# SIM3L168_A register map
File version: 1
CPU: 
Registers are 32-bit, read-write, reset 0x0 unless marked. A register's access mark holds for its fields unless they carry their own. Offsets are from the block's base; [hi:lo] are bit positions; {n}, {i} and the like mark numbered series; 'fields as' and 'values as' point back to an identical list.

## ACCTR_0
Base 0x40042000
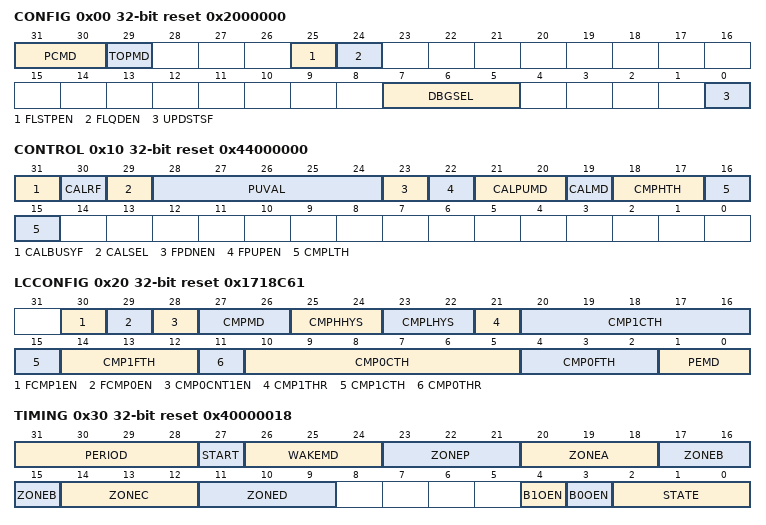
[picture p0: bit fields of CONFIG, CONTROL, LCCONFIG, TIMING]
0x00 CONFIG reset 0x2000000 — Configuration
  [31:30] PCMD — Pulse Counter Mode.
    0=DISABLED (Disable the pulse counter.); 1=SINGLE (Select single channel mode.); 2=DUAL (Select dual channel mode.); 3=QUADRATURE (Select quadrature mode.)
  [29] TOPMD — Topology Mode.
    0=SWITCH (Select the switch closure topology.); 1=LC (Select the LC resonant topology.)
  [25] FLSTPEN — Flutter Stop Enable.
    0=DISABLED (The pulse counter continues operating during a flutter event.); 1=ENABLED (The 24-bit counters stop counting during a flutter event.)
  [24] FLQDEN — Flutter Quadrature-to-Dual Switch Enable.
    0=DISABLED (The pulse counter remains in quadrature mode during a flutter event.); 1=ENABLED (The pulse counter switches from quadrature mode to dual mode during a flutter event.)
  [7:5] DBGSEL — Debug Signal Select.
    0=NONE (No debug signals output.); 1=LCC0_LCC1 ((LC Mode) DBG0 = CMP0OUT, DBG1 = CMP0OUT.); 2=LCC0_INT0 ((LC Mode) DBG0 = CMP0OUT, DBG1 = INTEG0.); 3=LCC1_INT1 ((LC Mode) DBG0 = CMP1OUT, DBG1 = INTEG1.); 4=INT0_INT1 ((Any Mode) DBG0 = INTEG0 DBG1 = INTEG1.); 5=CMP0_CMP1 ((Switch Mode) DBG0 = CMP0OUT, DBG1 = CMP0OUT.); 6=CMP0_INT0 ((Switch Mode) DBG0 = CMP0OUT, DBG1 = INTEG0.); 7=CMP1_INT1 ((Switch Mode) DBG0= CMP1OUT, DBG1 = INTEG1.)
  [0] UPDSTSF ro — Write Update Status Flag.
    0=NOT_SET (An internal pulse counter register update is not in progress.); 1=SET (An internal pulse counter register update is in progress.)
0x10 CONTROL reset 0x44000000
  [31] CALBUSYF — Calibration Busy Flag.
    0=NOT_SET (A calibration operation is not in progress.); 1=SET (A calibration operation is in progress. Hardware will clear this flag when the operation completes.)
  [30] CALRF ro — Calibration Result Flag.
    0=NOT_SET (The automatic calibration operation did not succeed.); 1=SET (The automatic calibration operation succeeded.)
  [29] CALSEL — Automatic Calibration Input Select.
    0=IN0 (Calibrate the IN0 input.); 1=IN1 (Calibrate the IN1 input.)
  [28:24] PUVAL — Pull-up Value.
  [23] FPDNEN — Force Ground Input Enable.
    0=DISABLED (Disable input grounding.); 1=ENABLED (Enable input grounding. The IN0 and IN1 inputs are grounded.)
  [22] FPUPEN — Force Continuous Pull-up Enable.
    0=DISABLED (Pull-ups are enabled automatically by hardware.); 1=ENABLED (Always enable the pull-ups.)
  [21:20] CALPUMD — Automatic Calibration Pull-up Mode.
    0=FULL (Use full pull-up mode.); 1=SMALL (Use small pull-up mode.); 2=MEDIUM (Use medium pull-up mode.); 3=LARGE (Use large pull-up mode.)
  [19] CALMD — Automatic Calibration Mode.
    0=UNTIL_PASS (Continue to calibrate until a passing condition occurs.); 1=UNTIL_FAIL (Continue to calibrate until a failing condition occurs.)
  [18:17] CMPHTH — Comparator High Threshold.
    0=48_PERCENT (Set the digital comparator high threshold to 48% of VIO.); 1=52_PERCENT (Set the digital comparator high threshold to 52% of VIO.); 2=56_PERCENT (Set the digital comparator high threshold to 56% of VIO.); 3=60_PERCENT (Set the digital comparator high threshold to 60% of VIO.)
  [16:15] CMPLTH — Comparator Low Threshold.
    0=32_PERCENT (Set the digital comparator low threshold to 32% of VIO.); 1=36_PERCENT (Set the digital comparator low threshold to 36% of VIO.); 2=40_PERCENT (Set the digital comparator low threshold to 40% of VIO.); 3=44_PERCENT (Set the digital comparator low threshold to 44% of VIO.)
0x20 LCCONFIG reset 0x1718C61 — LC Configuration
  [30] FCMP1EN — Force LC Comparator 1 On Enable.
    0=DISABLED (Hardware automatically turns LC comparator 1 on and off.); 1=ENABLED (Force LC comparator 1 always on.)
  [29] FCMP0EN — Force LC Comparator 0 On Enable.
    0=DISABLED (Hardware automatically turns LC comparator 0 on and off.); 1=ENABLED (Force LC comparator 0 always on.)
  [28] CMP0CNT1EN — LC Comparator 0 to Count 1 Enable.
    0=DISABLED (Use LC comparator 0 as an input to counter 0 and LC comparator 1 as an input to counter 1.); 1=ENABLED (Use LC comparator 0 as an input to both counter 0 and counter 1.)
  [27:26] CMPMD — LC Comparator Mode.
    0=5_US (Mode 0 (slowest response time, lowest power consumption).); 1=1_US (Mode 1.); 2=400_NS (Mode 2.); 3=200_NS (Mode 3 (fastest response time, highest power consumption).)
  [25:24] CMPHHYS — LC Comparator High-side Hysteresis.
    0=0_MV (Set both LC comparators to use 0 mV high-side hysteresis.); 1=5_MV (Set both LC comparators to use 5 mV high-side hysteresis.); 2=10_MV (Set both LC comparators to use 10 mV high-side hysteresis.); 3=20_MV (Set both LC comparators to use 20 mV high-side hysteresis.)
  [23:22] CMPLHYS — LC Comparator Low-side Hysteresis.
    0=0_MV (Set both LC comparators to use 0 mV low-side hysteresis.); 1=5_MV (Set both LC comparators to use 5 mV low-side hysteresis.); 2=10_MV (Set both LC comparators to use 10 mV low-side hysteresis.); 3=20_MV (Set both LC comparators to use 20 mV low-side hysteresis.)
  [21] CMP1THR — LC Comparator 1 Threshold Range.
    0=LOW (Set the comparator 1 threshold to the low range (0 V to VIO/8 in 48 steps).); 1=FULL (Set the comparator 1 threshold to a full range (0 V to VIO in 64 steps).)
  [20:15] CMP1CTH — LC Comparator 1 Coarse Threshold.
  [14:12] CMP1FTH — LC Comparator 1 Fine Threshold.
  [11] CMP0THR — LC Comparator 0 Threshold Range.
    0=LOW (Set the comparator 0 threshold to the low range (0 V to VIO/8 in 48 steps).); 1=FULL (Set the comparator 0 threshold to a full range (0 V to VIO in 64 steps).)
  [10:5] CMP0CTH — LC Comparator 0 Coarse Threshold.
  [4:2] CMP0FTH — LC Comparator 0 Fine Threshold.
  [1:0] PEMD — LC Pulse Extension Mode.
    0=LOW (Stretch the LC comparator output low pulses by approximately 20 ns.); 1=HIGH (Stretch the LC comparator output high pulses by approximately 20 ns.); 2=NONE (No pulse extension.)
0x30 TIMING reset 0x40000018
  [31:28] PERIOD — Pulse Counter Period.
    0=4_CYCLES (Set the period to 4 RTC cycles.); 1=8_CYCLES (Set the period to 8 RTC cycles.); 2=16_CYCLES (Set the period to 16 RTC cycles.); 3=32_CYCLES (Set the period to 32 RTC cycles.); 4=64_CYCLES (Set the period to 64 RTC cycles.); 5=128_CYCLES (Set the period to 128 RTC cycles.); 6=256_CYCLES (Set the period to 256 RTC cycles.); 7=512_CYCLES (Set the period to 512 RTC cycles.); 8=1024_CYCLES (Set the period to 1024 RTC cycles.); 9=2048_CYCLES (Set the period to 2048 RTC cycles.); 10=4096_CYCLES (Set the period to 4096 RTC cycles.); 14=SINGLE_SAMPLE (Set the module to single sample mode and disable the period counter after the next completion of the sequencer. In this mode, firmware must start each sample by setting FLCSEN to 1.); 15=CONSECUTIVE_SAMPLE (Set the module to consecutive sample mode and disable the period counter. After completing zone D, the timing engine will jump directly to zone A, skipping both the W and P zones.)
  [27] START — Sequencer Start.
    0=DISABLED (Do not start the sequencer.); 1=ENABLED (Start the sequencer.)
  [26:24] WAKEMD — LC Wake Mode.
    0=DISABLED (Disable wake up events.); 1=WZONEP (Wake or interrupt at the start of zone P.); 2=WZONEA (Wake or interrupt at the start of zone A.); 3=WZONEB (Wake or interrupt at the start of zone B.); 4=WZONEC (Wake or interrupt at the start of zone C.); 5=WZONED (Wake or interrupt at the start of zone D.); 6=WEND (Wake or interrupt at the end of the LC sequence.); 7=WKSTOP (Wake or interrupt at the end of the LC sequence and stop the sequencer when this event occurs.)
  [23:21] ZONEP — Zone P Count.
  [20:18] ZONEA — Zone A Count.
  [17:15] ZONEB — Zone B Count.
  [14:12] ZONEC — Zone C Count.
  [11:9] ZONED — Zone D Count.
  [4] B1OEN — Bias 1 Offset Enable.
    0=DISABLED (The bias 1 pulse is a full width (minimum 2 RTC cycles).); 1=ENABLED (The bias 1 pulse is delayed 1/2 an RTC cycle and de-asserts 1/2 an RTC cycle early (minimum 3 RTC cycles).)
  [3] B0OEN — Bias 0 Offset Enable.
    0=DISABLED (The bias 0 pulse is a full width (minimum 2 RTC cycles).); 1=ENABLED (The bias 0 pulse is delayed 1/2 an RTC cycle and de-asserts 1/2 an RTC cycle early (minimum 3 RTC cycles).)
  [2:0] STATE ro — Timing State.
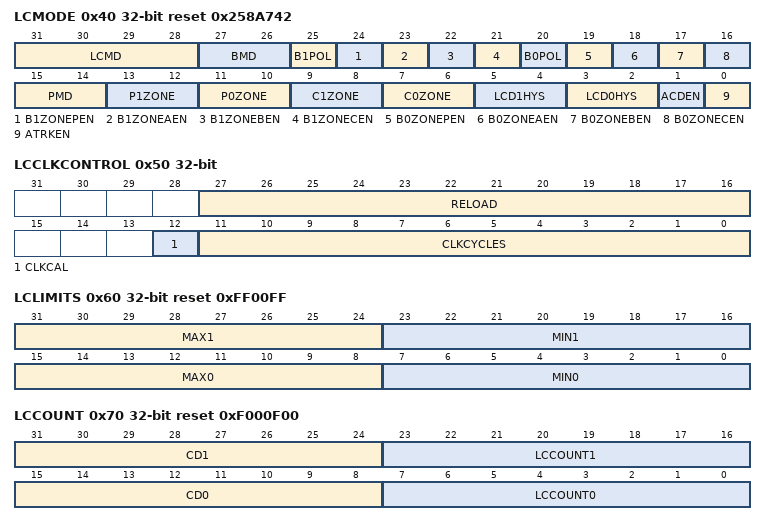
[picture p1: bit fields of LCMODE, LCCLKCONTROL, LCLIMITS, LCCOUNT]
0x40 LCMODE reset 0x258A742
  [31:28] LCMD — LC Mode.
    0=MODE0 (The LC pulse asserts throughout zone A or zone C with a single-ended comparator using the counter and discriminator.); 1=MODE1 (The LC pulse asserts throughout zone A or zone C with differential comparators using the counter and discriminator.); 2=MODE2 (The LC pulse asserts throughout zone A or zone C with a single-ended comparator sampling and holding at the end of the LC pulse.); 3=MODE3 (The LC pulse asserts throughout zone A or zone C with differential comparators sampling and holding at the end of the LC pulse.); 4=MODE4 (The LC pulse starts at the beginning of zone A or C and stops with the timer with a single-ended comparator using the counter and discriminator.); 5=MODE5 (The LC pulse starts at the beginning of zone A or C and stops with the timer with differential comparators using the counter and discriminator.); 6=MODE6 (The LC pulse starts at the beginning of zone A or C and stops with the timer with a single-ended comparator sampling and holding at the end of the LC pulse.); 7=MODE7 (The LC pulse starts at the beginning of zone A or C and stops with the timer with differential comparators sampling and holding at the end of the LC pulse.); 8=MODE8 (The LC pulse starts at beginning of zone A or C and stops with the rising edge of the external stop input (STOPx) with a single-ended comparator using the counter and discriminator.); 9=MODE9 (The LC pulse starts at beginning of zone A or C and stops with the falling edge of the external stop input (STOPx) with single-ended comparators using the counter and discriminator.); 10=MODE10 (The LC pulse starts at beginning of zone A or C and stops with the rising edge of the external stop input (STOPx) with a single-ended comparator sampling and holding at the end of the LC pulse.); 11=MODE11 (The LC pulse starts at beginning of zone A or C and stops with the falling edge of the external stop input (STOPx) with single-ended comparators sampling and holding at the end of the LC pulse.); 12=MODE12 (Do not generate a pulse with a single-ended comparator using the timer and discrimintor.); 13=MODE13 (Do not generate a pulse with differential comparators using the timer and discrimintor.); 14=MODE14 (Do not generate a pulse with a single-ended comparator sampling and holding at the end of the zone.); 15=MODE15 (Do not genreate a pulse with differential comparators sampling and holding at the end of the zone.)
  [27:26] BMD — Bias Mode.
    0=MODE0 (Disable the bias signals.); 1=MODE1 (Use the bias signals externally only (LCBIAS0 and LCBIAS1 outputs).); 2=MODE2 (Use the bias signals internally only.); 3=MODE3 (Use the bias signals externally (LCBIAS0 and LCBIAS1 outputs) and internally.)
  [25] B1POL — Bias 1 Polarity.
    0=PULSE_LOW (Set bias 1 to idle high, pulse low.); 1=PULSE_HIGH (Set bias 1 to idle low, pulse high.)
  [24] B1ZONEPEN — Bias 1 Zone P Enable.
    0=DISABLED (Disable bias 1 during zone P.); 1=ENABLED (Enable bias 1 during zone P.)
  [23] B1ZONEAEN — Bias 1 Zone A Enable.
    0=DISABLED (Disable bias 1 during zone A.); 1=ENABLED (Enable bias 1 during zone A.)
  [22] B1ZONEBEN — Bias 1 Zone B Enable.
    0=DISABLED (Disable bias 1 during zone B.); 1=ENABLED (Enable bias 1 during zone B.)
  [21] B1ZONECEN — Bias 1 Zone C Enable.
    0=DISABLED (Disable bias 1 during zone C.); 1=ENABLED (Enable bias 1 during zone C.)
  [20] B0POL — Bias 0 Polarity.
    0=PULSE_LOW (Set bias 0 to idle high, pulse low.); 1=PULSE_HIGH (Set bias 0 to idle low, pulse high.)
  [19] B0ZONEPEN — Bias 0 Zone P Enable.
    0=DISABLED (Disable bias 0 during zone P.); 1=ENABLED (Enable bias 0 during zone P.)
  [18] B0ZONEAEN — Bias 0 Zone A Enable.
    0=DISABLED (Disable bias 0 during zone A.); 1=ENABLED (Enable bias 0 during zone A.)
  [17] B0ZONEBEN — Bias 0 Zone B Enable.
    0=DISABLED (Disable bias 0 during zone B.); 1=ENABLED (Enable bias 0 during zone B.)
  [16] B0ZONECEN — Bias 0 Zone C Enable.
    0=DISABLED (Disable bias 0 during zone C.); 1=ENABLED (Enable bias 0 during zone C.)
  [15:14] PMD — LC Pulse Mode.
    0=DISABLED (Disable pulse mode.); 1=TOGGLE (Toggle at the start of zone A or zone C.); 2=PULSE_LOW (Set the pulse mode to idle high, pulse low.); 3=PULSE_HIGH (Set the pulse mode to idle low, pulse high.)
  [13:12] P1ZONE — Pulse 1 Active Zone Select.
    0=DISABLED (Disable the pulse 1 output (LCPUL1).); 1=C_ONLY (Select zone C only as the active zone for the pulse 1 output (LCPUL1).); 2=A_ONLY (Select zone A only as the active zone for the pulse 1 output (LCPUL1).); 3=A_AND_C (Select zones A and C as the active zones for the pulse 1 output (LCPUL1).)
  [11:10] P0ZONE — Pulse 0 Active Zone Select.
    0=DISABLED (Disable the pulse 0 output (LCPUL0).); 1=C_ONLY (Select zone C only as the active zone for the pulse 0 output (LCPUL0).); 2=A_ONLY (Select zone A only as the active zone for the pulse 0 output (LCPUL0).); 3=A_AND_C (Select zones A and C as the active zones for the pulse 0 output (LCPUL0).)
  [9:8] C1ZONE — Counter 1 Active Zone Select.
    0=ZONEA (Select zone A as the active zone for counter 1 (LCIN1 input).); 1=ZONEB (Select zone B as the active zone for counter 1 (LCIN1 input).); 2=ZONEC (Select zone C as the active zone for counter 1 (LCIN1 input).); 3=ZONED (Select zone D as the active zone for counter 1 (LCIN1 input).)
  [7:6] C0ZONE — Counter 0 Active Zone Select.
    0=ZONEA (Select zone A as the active zone for counter 0 (LCIN0 input).); 1=ZONEB (Select zone B as the active zone for counter 0 (LCIN0 input).); 2=ZONEC (Select zone C as the active zone for counter 0 (LCIN0 input).); 3=ZONED (Select zone D as the active zone for counter 0 (LCIN0 input).)
  [5:4] LCD1HYS — LC Discriminator 1 Digital Hysterisis.
    0=ZERO (A high-to-low transition occurs if LCCOUNT1 is less than CD1.); 1=MINUS1 (A high-to-low transition occurs if LCCOUNT1 is less than CD1 - 1.); 2=MINUS2 (A high-to-low transition occurs if LCCOUNT1 is less than CD1 - 2.); 3=MINUS3 (A high-to-low transition occurs if LCCOUNT1 is less than CD1 - 3.)
  [3:2] LCD0HYS — LC Discriminator 0 Digital Hysterisis.
    0=ZERO (A high-to-low transition occurs if LCCOUNT0 is less than CD0.); 1=MINUS1 (A high-to-low transition occurs if LCCOUNT0 is less than CD0 - 1.); 2=MINUS2 (A high-to-low transition occurs if LCCOUNT0 is less than CD0 - 2.); 3=MINUS3 (A high-to-low transition occurs if LCCOUNT0 is less than CD0 - 3.)
  [1] ACDEN — Automatic Center Discriminator Enable.
    0=DISABLED (Disable automatic center discriminator mode. Firmware must set the CD0 and CD1 fields.); 1=ENABLED (Enable automatic center discriminator mode. Hardware will keep the CD0 and CD1 fields centered between MAX and MIN.)
  [0] ATRKEN — Automatic Tracking Enable.
    0=DISABLED (Disable automatic tracking.); 1=ENABLED (Enable automatic tracking. A new MAX value of any size will increase both the MAX and MIN by 1, and a new MIN value of any size will decrease both the MAX and MIN by 1.)
0x50 LCCLKCONTROL — LC Clock Control
  [27:16] RELOAD — LC Oscillator Reload Value.
  [12] CLKCAL — LC Oscillator Calibration Start.
    0=NOT_IN_PROGRESS (A calibration operation is not in progress.); 1=START (Start an oscillator calibration or a calibration operation is in progress.)
  [11:0] CLKCYCLES ro — LC Oscillator Clock Cycles.
0x60 LCLIMITS reset 0xFF00FF — LC Counter Limits
  [31:24] MAX1 ro — LC Counter 1 Maximum Value.
  [23:16] MIN1 ro — LC Counter 1 Minimum Value.
  [15:8] MAX0 ro — LC Counter 0 Maximum Value.
  [7:0] MIN0 ro — LC Counter 0 Minimum Value.
0x70 LCCOUNT reset 0xF000F00 — LC Counters
  [31:24] CD1 — LC Counter 1 Discriminator.
  [23:16] LCCOUNT1 ro — LC Counter 1.
  [15:8] CD0 — LC Counter 0 Discriminator.
  [7:0] LCCOUNT0 ro — LC Counter 0.
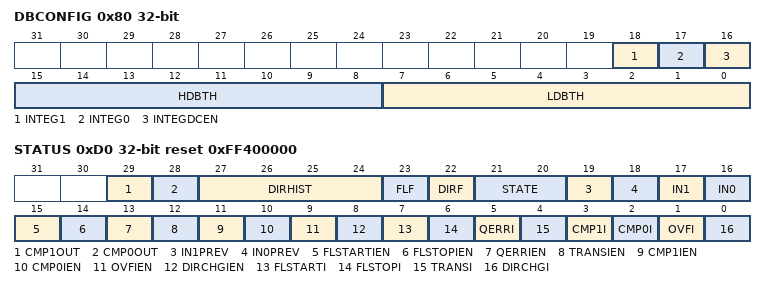
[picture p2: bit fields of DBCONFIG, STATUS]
0x80 DBCONFIG — Pulse Counter Debounce Configuration
  [18] INTEG1 ro — PC Integrator 1 Output.
    0=LOW (The integrator 1 output is low.); 1=HIGH (The integrator 1 output is high.)
  [17] INTEG0 ro — PC Integrator 0 Output.
    0=LOW (The integrator 0 output is low.); 1=HIGH (The integrator 0 output is high.)
  [16] INTEGDCEN — PC Integrator Disconnect Enable.
    0=DISABLED (Connect integrator to 24 bit counter state machine logic.); 1=ENABLED (Disconnect the integrators from the IN0 and IN1 inputs.)
  [15:8] HDBTH — Integrator High Debounce.
  [7:0] LDBTH — Integrator Low Debounce.
0x90 COUNT0 — Pulse Counter 0
  [23:0] COUNT0 ro — Pulse Counter 0.
0xA0 COUNT1 — Pulse Counter 1
  [23:0] COUNT1 ro — Pulse Counter 1.
0xB0 COMP0 reset 0xFFFFFF — Comparator 0
  [23:0] COMP0 — Pulse Counter Comparator 0 Threshold.
0xC0 COMP1 reset 0xFFFFFF — Pulse Counter Comparator 1 Threshold
  [23:0] COMP1 — Pulse Counter Comparator 1 Threshold.
0xD0 STATUS reset 0xFF400000 — Pulse Counter Status
  [29] CMP1OUT ro — Comparator 1 Output.
    0=LOW (The output of comparator 1 is low.); 1=HIGH (The output of comparator1 is high.)
  [28] CMP0OUT ro — Comparator 0 Output.
    0=LOW (The output of comparator 0 is low.); 1=HIGH (The output of comparator 0 is high.)
  [27:24] DIRHIST ro — Direction History .
  [23] FLF ro — Flutter Detected Flag.
    0=NOT_SET (The switch operates normally.); 1=SET (A flutter event was detected.)
  [22] DIRF ro — Direction Flag.
    0=COUNTER_CLOCKWISE (The current direction is counter-clockwise.); 1=CLOCKWISE (The current direction is clockwise.)
  [21:20] STATE ro — Pulse Counter State.
    {v}=ST{v} (The pulse counter is in state {v}.) (v=0..3)
  [19] IN1PREV ro — Previous Integrator 1 Output.
    0=LOW (The previous integrator 1 output was low.); 1=HIGH (The previous integrator 1 output was high.)
  [18] IN0PREV ro — Previous Integrator 0 Output.
    0=LOW (The previous integrator 0 output was low.); 1=HIGH (The previous integrator 0 output was high.)
  [17] IN1 ro — Integrator 1 Output.
    values as DBCONFIG.INTEG1
  [16] IN0 ro — Integrator 0 Output.
    values as DBCONFIG.INTEG0
  [15] FLSTARTIEN — Flutter Start Interrupt Enable.
    0=DISABLED (Disable flutter detection start events as an interrupt or wake up source.); 1=ENABLED (Enable flutter detection start events as an interrupt or wake up source.)
  [14] FLSTOPIEN — Flutter Stop Interrupt Enable.
    0=DISABLED (Disable flutter detection end events as an interrupt or wake up source.); 1=ENABLED (Enable flutter detection end events as an interrupt or wake up source.)
  [13] QERRIEN — Quadrature Error Interrupt Enable.
    0=DISABLED (Disable quadrature error as an interrupt or wake up source.); 1=ENABLED (Enable quadrature error as an interrupt or wake up source.)
  [12] TRANSIEN — Integrator Transition Interrupt Enable.
    0=DISABLED (Disable integrator transitions as an interrupt or wake up source.); 1=ENABLED (Enable integrator transitions as an interrupt or wake up source.)
  [11] CMP1IEN — Digital Comparator 1 Interrupt Enable.
    0=DISABLED (Disable comparator 1 as an interrupt or wake up source.); 1=ENABLED (Enable comparator 1 as an interrupt or wake up source.)
  [10] CMP0IEN — Digital Comparator 0 Interrupt Enable.
    0=DISABLED (Disable comparator 0 as an interrupt or wake up source.); 1=ENABLED (Enable comparator 0 as an interrupt or wake up source.)
  [9] OVFIEN — Counter Overflow Interrupt Enable.
    0=DISABLED (Disable counter overflows as an interrupt or wake up source.); 1=ENABLED (Enable counter overflows as an interrupt or wake up source.)
  [8] DIRCHGIEN — Direction Change Interrupt Enable.
    0=DISABLED (Disable direction change as an interrupt or wake up source.); 1=ENABLED (Enable direction change as an interrupt or wake up source.)
  [7] FLSTARTI — Flutter Start Interrupt Flag.
    0=NOT_SET (A flutter detection start event did not occur.); 1=SET (A flutter detection start event occurred.)
  [6] FLSTOPI — Flutter Stop Interrupt Flag.
    0=NOT_SET (A flutter detection end event did not occur.); 1=SET (A flutter detection end event occurred.)
  [5] QERRI — Quadrature Error Interrupt Flag.
    0=NOT_SET (A quadrature error did not occur.); 1=SET (A quadrature error occurred.)
  [4] TRANSI — Integrator Transition Interrupt Flag.
    0=NOT_SET (An integrator output transition did not occur.); 1=SET (An integrator output transition occurred.)
  [3] CMP1I — Digital Comparator 1 Interrupt Flag.
    0=NOT_SET (A digital comparator 1 and counter 1 match did not occur.); 1=SET (A digital comparator 1 and counter 1 match occurred.)
  [2] CMP0I — Digital Comparator 0 Interrupt Flag.
    0=NOT_SET (A digital comparator 0 and counter 0 match did not occur.); 1=SET (A digital comparator 0 and counter 0 match occurred.)
  [1] OVFI — Counter Overflow Interrupt Flag.
    0=NOT_SET (Neither of the counters overflowed.); 1=SET (One of the counters overflowed.)
  [0] DIRCHGI — Direction Change Interrupt Flag.
    0=NOT_SET (A direction change did not occur.); 1=SET (A direction change occurred.)
0xE0 DEBUGEN reset 0x624 — Calibration
  [14] DBGOEN — Debug Output Enable.
    0=DISABLED; 1=ENABLED
